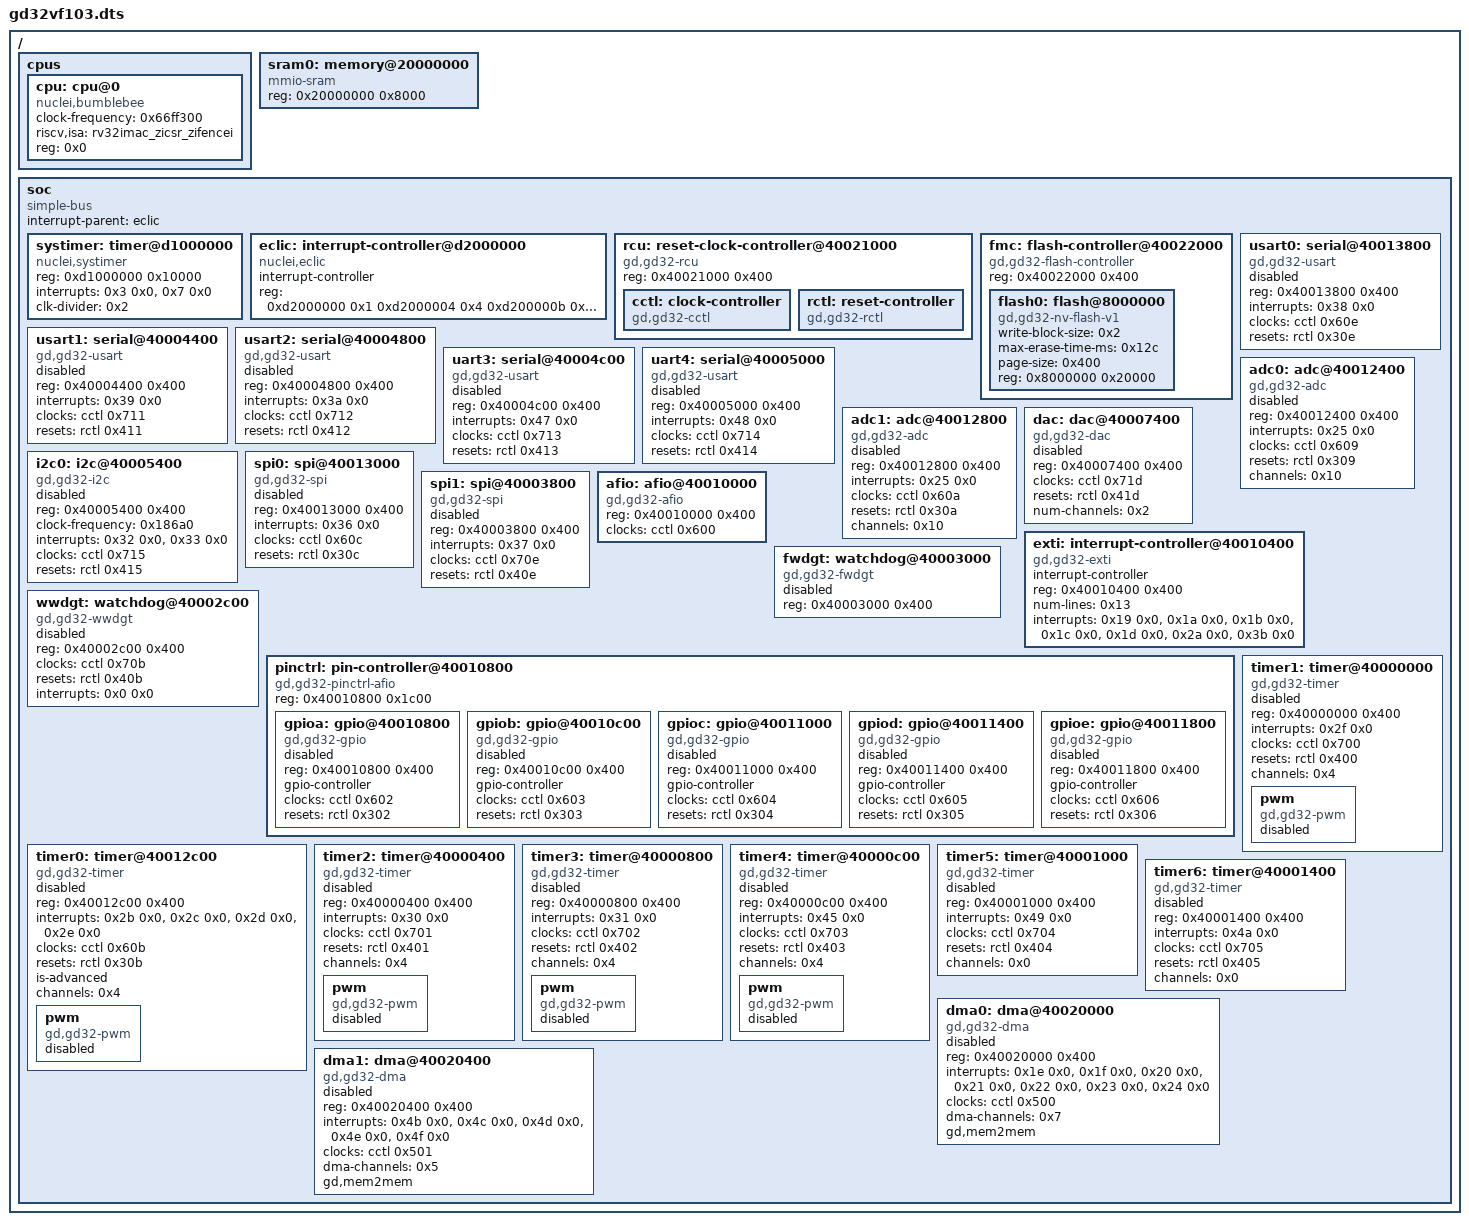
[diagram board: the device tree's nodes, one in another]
/dts-v1/;

/ {
	#address-cells = < 0x1 >;
	#size-cells = < 0x1 >;
	cpus {
		#address-cells = < 0x1 >;
		#size-cells = < 0x0 >;
		cpu: cpu@0 {
			clock-frequency = < 0x66ff300 >;
			compatible = "nuclei,bumblebee", "riscv";
			riscv,isa = "rv32imac_zicsr_zifencei";
			reg = < 0x0 >;
		};
	};
	sram0: memory@20000000 {
		compatible = "mmio-sram";
		reg = < 0x20000000 0x8000 >;
	};
	soc {
		#address-cells = < 0x1 >;
		#size-cells = < 0x1 >;
		compatible = "simple-bus";
		interrupt-parent = < &eclic >;
		ranges;
		systimer: timer@d1000000 {
			compatible = "nuclei,systimer";
			reg = < 0xd1000000 0x10000 >;
			interrupts = < 0x3 0x0 >, < 0x7 0x0 >;
			clk-divider = < 0x2 >;
		};
		eclic: interrupt-controller@d2000000 {
			compatible = "nuclei,eclic";
			#address-cells = < 0x0 >;
			#interrupt-cells = < 0x2 >;
			interrupt-controller;
			reg = < 0xd2000000 0x1 0xd2000004 0x4 0xd200000b 0x1 0xd2001000 0x1000 >;
			phandle = < 0x1 >;
		};
		rcu: reset-clock-controller@40021000 {
			compatible = "gd,gd32-rcu";
			reg = < 0x40021000 0x400 >;
			status = "okay";
			cctl: clock-controller {
				compatible = "gd,gd32-cctl";
				#clock-cells = < 0x1 >;
				status = "okay";
				phandle = < 0x2 >;
			};
			rctl: reset-controller {
				compatible = "gd,gd32-rctl";
				#reset-cells = < 0x1 >;
				status = "okay";
				phandle = < 0x3 >;
			};
		};
		fmc: flash-controller@40022000 {
			compatible = "gd,gd32-flash-controller";
			reg = < 0x40022000 0x400 >;
			#address-cells = < 0x1 >;
			#size-cells = < 0x1 >;
			flash0: flash@8000000 {
				compatible = "gd,gd32-nv-flash-v1", "soc-nv-flash";
				write-block-size = < 0x2 >;
				max-erase-time-ms = < 0x12c >;
				page-size = < 0x400 >;
				reg = < 0x8000000 0x20000 >;
			};
		};
		usart0: serial@40013800 {
			compatible = "gd,gd32-usart";
			reg = < 0x40013800 0x400 >;
			interrupts = < 0x38 0x0 >;
			clocks = < &cctl 0x60e >;
			resets = < &rctl 0x30e >;
			status = "disabled";
		};
		usart1: serial@40004400 {
			compatible = "gd,gd32-usart";
			reg = < 0x40004400 0x400 >;
			interrupts = < 0x39 0x0 >;
			clocks = < &cctl 0x711 >;
			resets = < &rctl 0x411 >;
			status = "disabled";
		};
		usart2: serial@40004800 {
			compatible = "gd,gd32-usart";
			reg = < 0x40004800 0x400 >;
			interrupts = < 0x3a 0x0 >;
			clocks = < &cctl 0x712 >;
			resets = < &rctl 0x412 >;
			status = "disabled";
		};
		uart3: serial@40004c00 {
			compatible = "gd,gd32-usart";
			reg = < 0x40004c00 0x400 >;
			interrupts = < 0x47 0x0 >;
			clocks = < &cctl 0x713 >;
			resets = < &rctl 0x413 >;
			status = "disabled";
		};
		uart4: serial@40005000 {
			compatible = "gd,gd32-usart";
			reg = < 0x40005000 0x400 >;
			interrupts = < 0x48 0x0 >;
			clocks = < &cctl 0x714 >;
			resets = < &rctl 0x414 >;
			status = "disabled";
		};
		adc0: adc@40012400 {
			compatible = "gd,gd32-adc";
			reg = < 0x40012400 0x400 >;
			interrupts = < 0x25 0x0 >;
			clocks = < &cctl 0x609 >;
			resets = < &rctl 0x309 >;
			channels = < 0x10 >;
			status = "disabled";
			#io-channel-cells = < 0x1 >;
		};
		adc1: adc@40012800 {
			compatible = "gd,gd32-adc";
			reg = < 0x40012800 0x400 >;
			interrupts = < 0x25 0x0 >;
			clocks = < &cctl 0x60a >;
			resets = < &rctl 0x30a >;
			channels = < 0x10 >;
			status = "disabled";
			#io-channel-cells = < 0x1 >;
		};
		dac: dac@40007400 {
			compatible = "gd,gd32-dac";
			reg = < 0x40007400 0x400 >;
			clocks = < &cctl 0x71d >;
			resets = < &rctl 0x41d >;
			num-channels = < 0x2 >;
			status = "disabled";
			#io-channel-cells = < 0x1 >;
		};
		i2c0: i2c@40005400 {
			compatible = "gd,gd32-i2c";
			reg = < 0x40005400 0x400 >;
			#address-cells = < 0x1 >;
			#size-cells = < 0x0 >;
			clock-frequency = < 0x186a0 >;
			interrupts = < 0x32 0x0 >, < 0x33 0x0 >;
			interrupt-names = "event", "error";
			clocks = < &cctl 0x715 >;
			resets = < &rctl 0x415 >;
			status = "disabled";
		};
		spi0: spi@40013000 {
			compatible = "gd,gd32-spi";
			reg = < 0x40013000 0x400 >;
			interrupts = < 0x36 0x0 >;
			clocks = < &cctl 0x60c >;
			resets = < &rctl 0x30c >;
			status = "disabled";
			#address-cells = < 0x1 >;
			#size-cells = < 0x0 >;
		};
		spi1: spi@40003800 {
			compatible = "gd,gd32-spi";
			reg = < 0x40003800 0x400 >;
			interrupts = < 0x37 0x0 >;
			clocks = < &cctl 0x70e >;
			resets = < &rctl 0x40e >;
			status = "disabled";
			#address-cells = < 0x1 >;
			#size-cells = < 0x0 >;
		};
		afio: afio@40010000 {
			compatible = "gd,gd32-afio";
			reg = < 0x40010000 0x400 >;
			clocks = < &cctl 0x600 >;
			status = "okay";
		};
		exti: interrupt-controller@40010400 {
			compatible = "gd,gd32-exti";
			#address-cells = < 0x0 >;
			interrupt-controller;
			#interrupt-cells = < 0x1 >;
			reg = < 0x40010400 0x400 >;
			num-lines = < 0x13 >;
			interrupts = < 0x19 0x0 >, < 0x1a 0x0 >, < 0x1b 0x0 >, < 0x1c 0x0 >, < 0x1d 0x0 >, < 0x2a 0x0 >, < 0x3b 0x0 >;
			interrupt-names = "line0", "line1", "line2", "line3", "line4", "line5-9", "line10-15";
			status = "okay";
		};
		fwdgt: watchdog@40003000 {
			compatible = "gd,gd32-fwdgt";
			reg = < 0x40003000 0x400 >;
			status = "disabled";
		};
		wwdgt: watchdog@40002c00 {
			compatible = "gd,gd32-wwdgt";
			reg = < 0x40002c00 0x400 >;
			clocks = < &cctl 0x70b >;
			resets = < &rctl 0x40b >;
			interrupts = < 0x0 0x0 >;
			status = "disabled";
		};
		pinctrl: pin-controller@40010800 {
			compatible = "gd,gd32-pinctrl-afio";
			reg = < 0x40010800 0x1c00 >;
			#address-cells = < 0x1 >;
			#size-cells = < 0x1 >;
			status = "okay";
			gpioa: gpio@40010800 {
				compatible = "gd,gd32-gpio";
				reg = < 0x40010800 0x400 >;
				gpio-controller;
				#gpio-cells = < 0x2 >;
				clocks = < &cctl 0x602 >;
				resets = < &rctl 0x302 >;
				status = "disabled";
			};
			gpiob: gpio@40010c00 {
				compatible = "gd,gd32-gpio";
				reg = < 0x40010c00 0x400 >;
				gpio-controller;
				#gpio-cells = < 0x2 >;
				clocks = < &cctl 0x603 >;
				resets = < &rctl 0x303 >;
				status = "disabled";
			};
			gpioc: gpio@40011000 {
				compatible = "gd,gd32-gpio";
				reg = < 0x40011000 0x400 >;
				gpio-controller;
				#gpio-cells = < 0x2 >;
				clocks = < &cctl 0x604 >;
				resets = < &rctl 0x304 >;
				status = "disabled";
			};
			gpiod: gpio@40011400 {
				compatible = "gd,gd32-gpio";
				reg = < 0x40011400 0x400 >;
				gpio-controller;
				#gpio-cells = < 0x2 >;
				clocks = < &cctl 0x605 >;
				resets = < &rctl 0x305 >;
				status = "disabled";
			};
			gpioe: gpio@40011800 {
				compatible = "gd,gd32-gpio";
				reg = < 0x40011800 0x400 >;
				gpio-controller;
				#gpio-cells = < 0x2 >;
				clocks = < &cctl 0x606 >;
				resets = < &rctl 0x306 >;
				status = "disabled";
			};
		};
		timer0: timer@40012c00 {
			compatible = "gd,gd32-timer";
			reg = < 0x40012c00 0x400 >;
			interrupts = < 0x2b 0x0 >, < 0x2c 0x0 >, < 0x2d 0x0 >, < 0x2e 0x0 >;
			interrupt-names = "brk", "up", "trgcom", "cc";
			clocks = < &cctl 0x60b >;
			resets = < &rctl 0x30b >;
			is-advanced;
			channels = < 0x4 >;
			status = "disabled";
			pwm {
				compatible = "gd,gd32-pwm";
				status = "disabled";
				#pwm-cells = < 0x3 >;
			};
		};
		timer1: timer@40000000 {
			compatible = "gd,gd32-timer";
			reg = < 0x40000000 0x400 >;
			interrupts = < 0x2f 0x0 >;
			interrupt-names = "global";
			clocks = < &cctl 0x700 >;
			resets = < &rctl 0x400 >;
			channels = < 0x4 >;
			status = "disabled";
			pwm {
				compatible = "gd,gd32-pwm";
				status = "disabled";
				#pwm-cells = < 0x3 >;
			};
		};
		timer2: timer@40000400 {
			compatible = "gd,gd32-timer";
			reg = < 0x40000400 0x400 >;
			interrupts = < 0x30 0x0 >;
			interrupt-names = "global";
			clocks = < &cctl 0x701 >;
			resets = < &rctl 0x401 >;
			channels = < 0x4 >;
			status = "disabled";
			pwm {
				compatible = "gd,gd32-pwm";
				status = "disabled";
				#pwm-cells = < 0x3 >;
			};
		};
		timer3: timer@40000800 {
			compatible = "gd,gd32-timer";
			reg = < 0x40000800 0x400 >;
			interrupts = < 0x31 0x0 >;
			interrupt-names = "global";
			clocks = < &cctl 0x702 >;
			resets = < &rctl 0x402 >;
			channels = < 0x4 >;
			status = "disabled";
			pwm {
				compatible = "gd,gd32-pwm";
				status = "disabled";
				#pwm-cells = < 0x3 >;
			};
		};
		timer4: timer@40000c00 {
			compatible = "gd,gd32-timer";
			reg = < 0x40000c00 0x400 >;
			interrupts = < 0x45 0x0 >;
			interrupt-names = "global";
			clocks = < &cctl 0x703 >;
			resets = < &rctl 0x403 >;
			channels = < 0x4 >;
			status = "disabled";
			pwm {
				compatible = "gd,gd32-pwm";
				status = "disabled";
				#pwm-cells = < 0x3 >;
			};
		};
		timer5: timer@40001000 {
			compatible = "gd,gd32-timer";
			reg = < 0x40001000 0x400 >;
			interrupts = < 0x49 0x0 >;
			interrupt-names = "global";
			clocks = < &cctl 0x704 >;
			resets = < &rctl 0x404 >;
			channels = < 0x0 >;
			status = "disabled";
		};
		timer6: timer@40001400 {
			compatible = "gd,gd32-timer";
			reg = < 0x40001400 0x400 >;
			interrupts = < 0x4a 0x0 >;
			interrupt-names = "global";
			clocks = < &cctl 0x705 >;
			resets = < &rctl 0x405 >;
			channels = < 0x0 >;
			status = "disabled";
		};
		dma0: dma@40020000 {
			compatible = "gd,gd32-dma";
			reg = < 0x40020000 0x400 >;
			interrupts = < 0x1e 0x0 >, < 0x1f 0x0 >, < 0x20 0x0 >, < 0x21 0x0 >, < 0x22 0x0 >, < 0x23 0x0 >, < 0x24 0x0 >;
			clocks = < &cctl 0x500 >;
			dma-channels = < 0x7 >;
			gd,mem2mem;
			#dma-cells = < 0x2 >;
			status = "disabled";
		};
		dma1: dma@40020400 {
			compatible = "gd,gd32-dma";
			reg = < 0x40020400 0x400 >;
			interrupts = < 0x4b 0x0 >, < 0x4c 0x0 >, < 0x4d 0x0 >, < 0x4e 0x0 >, < 0x4f 0x0 >;
			clocks = < &cctl 0x501 >;
			dma-channels = < 0x5 >;
			gd,mem2mem;
			#dma-cells = < 0x2 >;
			status = "disabled";
		};
	};
};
